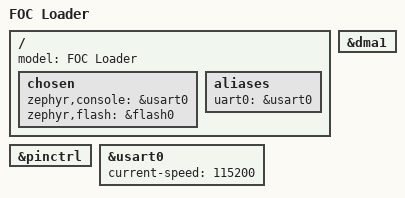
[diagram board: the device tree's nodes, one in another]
&pinctrl { status = "okay"; };
&dma1 { status = "okay"; };
&usart0 { status = "okay"; current-speed = <115200>; };
/ { model = "FOC Loader";
    chosen { zephyr,console = &usart0; zephyr,flash = &flash0; };
    aliases { uart0 = &usart0; };
};
